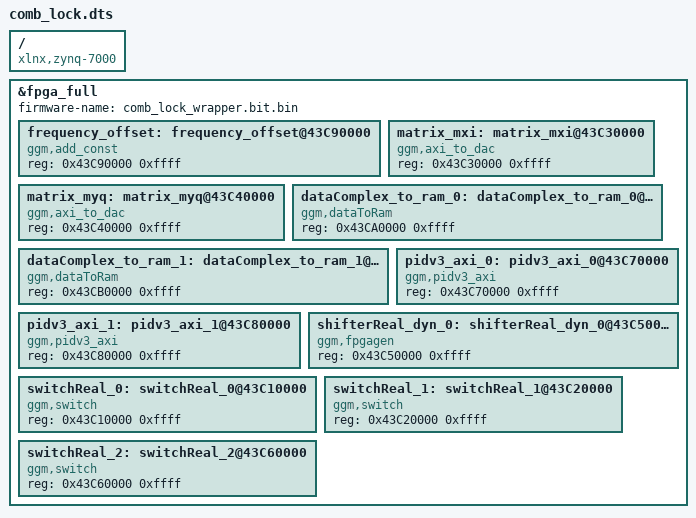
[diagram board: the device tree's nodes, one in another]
/dts-v1/;
/plugin/;

/ {
	compatible = "xlnx,zynq-7000";

	fragment0 {
		target = <&fpga_full>;
		__overlay__ {
			#address-cells = <1>;
			#size-cells = <1>;

			firmware-name = "comb_lock_wrapper.bit.bin";

			frequency_offset: frequency_offset@43C90000{
				compatible = "ggm,add_const";
				reg = <0x43C90000 0xffff>;
			};

			matrix_mxi: matrix_mxi@43C30000{
				compatible = "ggm,axi_to_dac";
				reg = <0x43C30000 0xffff>;
			};

			matrix_myq: matrix_myq@43C40000{
				compatible = "ggm,axi_to_dac";
				reg = <0x43C40000 0xffff>;
			};

			dataComplex_to_ram_0: dataComplex_to_ram_0@43CA0000{
				compatible = "ggm,dataToRam";
				reg = <0x43CA0000 0xffff>;
			};

			dataComplex_to_ram_1: dataComplex_to_ram_1@43CB0000{
				compatible = "ggm,dataToRam";
				reg = <0x43CB0000 0xffff>;
			};

			pidv3_axi_0: pidv3_axi_0@43C70000{
				compatible = "ggm,pidv3_axi";
				reg = <0x43C70000 0xffff>;
			};

			pidv3_axi_1: pidv3_axi_1@43C80000{
				compatible = "ggm,pidv3_axi";
				reg = <0x43C80000 0xffff>;
			};

			shifterReal_dyn_0: shifterReal_dyn_0@43C50000{
				compatible = "ggm,fpgagen";
				reg = <0x43C50000 0xffff>;
			};

			switchReal_0: switchReal_0@43C10000{
				compatible = "ggm,switch";
				reg = <0x43C10000 0xffff>;
			};

			switchReal_1: switchReal_1@43C20000{
				compatible = "ggm,switch";
				reg = <0x43C20000 0xffff>;
			};

			switchReal_2: switchReal_2@43C60000{
				compatible = "ggm,switch";
				reg = <0x43C60000 0xffff>;
			};

		};
	};
};
